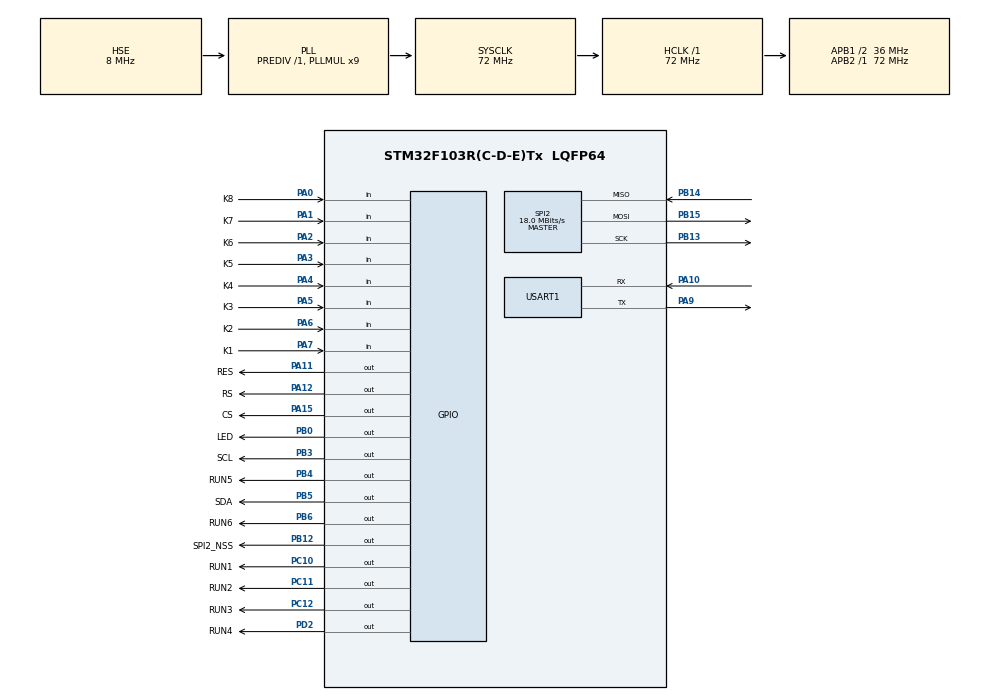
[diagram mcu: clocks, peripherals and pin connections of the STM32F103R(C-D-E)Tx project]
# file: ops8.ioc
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Dma.Request0=SPI2_TX
Dma.Request1=SPI2_RX
Dma.SPI2_RX.1.Direction=DMA_PERIPH_TO_MEMORY
Dma.SPI2_RX.1.Instance=DMA1_Channel4
Dma.SPI2_RX.1.MemDataAlignment=DMA_MDATAALIGN_BYTE
Dma.SPI2_RX.1.MemInc=DMA_MINC_ENABLE
Dma.SPI2_RX.1.Mode=DMA_NORMAL
Dma.SPI2_RX.1.PeriphDataAlignment=DMA_PDATAALIGN_BYTE
Dma.SPI2_RX.1.PeriphInc=DMA_PINC_DISABLE
Dma.SPI2_RX.1.Priority=DMA_PRIORITY_LOW
Dma.SPI2_TX.0.Direction=DMA_MEMORY_TO_PERIPH
Dma.SPI2_TX.0.Instance=DMA1_Channel5
Dma.SPI2_TX.0.MemDataAlignment=DMA_MDATAALIGN_BYTE
Dma.SPI2_TX.0.MemInc=DMA_MINC_ENABLE
Dma.SPI2_TX.0.Mode=DMA_NORMAL
Dma.SPI2_TX.0.PeriphDataAlignment=DMA_PDATAALIGN_BYTE
Dma.SPI2_TX.0.PeriphInc=DMA_PINC_DISABLE
Dma.SPI2_TX.0.Priority=DMA_PRIORITY_LOW
Mcu.Family=STM32F1
Mcu.Name=STM32F103R(C-D-E)Tx
Mcu.Package=LQFP64
NVIC.DMA1_Channel4_IRQn=true\:0\:0\:false\:false\:true\:false
NVIC.DMA1_Channel5_IRQn=true\:0\:0\:false\:false\:true\:false
NVIC.PriorityGroup=NVIC_PRIORITYGROUP_4
NVIC.SPI2_IRQn=true\:0\:0\:false\:false\:true\:true
NVIC.USART1_IRQn=true\:0\:0\:false\:false\:true\:true
PA0-WKUP.GPIO_Label=K8
PA0-WKUP.Signal=GPIO_Input
PA1.GPIO_Label=K7
PA1.Signal=GPIO_Input
PA10.Mode=Asynchronous
PA10.Signal=USART1_RX
PA11.GPIO_Label=RES
PA11.Signal=GPIO_Output
PA12.GPIO_Label=RS
PA12.Signal=GPIO_Output
PA15.GPIO_Label=CS
PA15.Signal=GPIO_Output
PA2.GPIO_Label=K6
PA2.Signal=GPIO_Input
PA3.GPIO_Label=K5
PA3.Signal=GPIO_Input
PA4.GPIO_Label=K4
PA4.Signal=GPIO_Input
PA5.GPIO_Label=K3
PA5.Signal=GPIO_Input
PA6.GPIO_Label=K2
PA6.Signal=GPIO_Input
PA7.GPIO_Label=K1
PA7.Signal=GPIO_Input
PA9.Mode=Asynchronous
PA9.Signal=USART1_TX
PB0.GPIO_Label=LED
PB0.Signal=GPIO_Output
PB12.GPIO_Label=SPI2_NSS
PB12.Signal=GPIO_Output
PB13.Mode=Full_Duplex_Master
PB13.Signal=SPI2_SCK
PB14.Mode=Full_Duplex_Master
PB14.Signal=SPI2_MISO
PB15.Mode=Full_Duplex_Master
PB15.Signal=SPI2_MOSI
PB3.GPIO_Label=SCL
PB3.Signal=GPIO_Output
PB4.GPIO_Label=RUN5
PB4.Signal=GPIO_Output
PB5.GPIO_Label=SDA
PB5.Signal=GPIO_Output
PB6.GPIO_Label=RUN6
PB6.Signal=GPIO_Output
PC10.GPIO_Label=RUN1
PC10.Signal=GPIO_Output
PC11.GPIO_Label=RUN2
PC11.Signal=GPIO_Output
PC12.GPIO_Label=RUN3
PC12.Signal=GPIO_Output
PD0-OSC_IN.Mode=HSE-External-Oscillator
PD0-OSC_IN.Signal=RCC_OSC_IN
PD1-OSC_OUT.Mode=HSE-External-Oscillator
PD1-OSC_OUT.Signal=RCC_OSC_OUT
PD2.GPIO_Label=RUN4
PD2.Signal=GPIO_Output
ProjectManager.HeapSize=0x200
ProjectManager.StackSize=0x400
ProjectManager.TargetToolchain=MDK-ARM V5
RCC.AHBFreq_Value=72000000
RCC.APB1CLKDivider=RCC_HCLK_DIV2
RCC.APB1Freq_Value=36000000
RCC.APB1TimFreq_Value=72000000
RCC.APB2Freq_Value=72000000
RCC.APB2TimFreq_Value=72000000
RCC.HCLKFreq_Value=72000000
RCC.PLLMUL=RCC_PLL_MUL9
RCC.PLLSourceVirtual=RCC_PLLSOURCE_HSE
RCC.SYSCLKFreq_VALUE=72000000
RCC.SYSCLKSource=RCC_SYSCLKSOURCE_PLLCLK
RCC.USBFreq_Value=72000000
SPI2.BaudRatePrescaler=SPI_BAUDRATEPRESCALER_2
SPI2.CLKPhase=SPI_PHASE_2EDGE
SPI2.CLKPolarity=SPI_POLARITY_HIGH
SPI2.CalculateBaudRate=18.0 MBits/s
SPI2.Direction=SPI_DIRECTION_2LINES
SPI2.Mode=SPI_MODE_MASTER
SPI2.VirtualType=VM_MASTER
USART1.VirtualMode=VM_ASYNC
VP_SYS_VS_ND.Mode=No_Debug
board=ops8

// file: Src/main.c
/**
  ******************************************************************************
  * @file           : main.c
  * @brief          : Main program body
  ******************************************************************************
  ** This notice applies to any and all portions of this file
  * that are not between comment pairs USER CODE BEGIN and
  * USER CODE END. Other portions of this file, whether
  * inserted by the user or by software development tools
  * are owned by their respective copyright owners.
  *
  * COPYRIGHT(c) 2018 STMicroelectronics
  *
  * Redistribution and use in source and binary forms, with or without modification,
  * are permitted provided that the following conditions are met:
  *   1. Redistributions of source code must retain the above copyright notice,
  *      this list of conditions and the following disclaimer.
  *   2. Redistributions in binary form must reproduce the above copyright notice,
  *      this list of conditions and the following disclaimer in the documentation
  *      and/or other materials provided with the distribution.
  *   3. Neither the name of STMicroelectronics nor the names of its contributors
  *      may be used to endorse or promote products derived from this software
  *      without specific prior written permission.
  *
  * THIS SOFTWARE IS PROVIDED BY THE COPYRIGHT HOLDERS AND CONTRIBUTORS "AS IS"
  * AND ANY EXPRESS OR IMPLIED WARRANTIES, INCLUDING, BUT NOT LIMITED TO, THE
  * IMPLIED WARRANTIES OF MERCHANTABILITY AND FITNESS FOR A PARTICULAR PURPOSE ARE
  * DISCLAIMED. IN NO EVENT SHALL THE COPYRIGHT HOLDER OR CONTRIBUTORS BE LIABLE
  * FOR ANY DIRECT, INDIRECT, INCIDENTAL, SPECIAL, EXEMPLARY, OR CONSEQUENTIAL
  * DAMAGES (INCLUDING, BUT NOT LIMITED TO, PROCUREMENT OF SUBSTITUTE GOODS OR
  * SERVICES; LOSS OF USE, DATA, OR PROFITS; OR BUSINESS INTERRUPTION) HOWEVER
  * CAUSED AND ON ANY THEORY OF LIABILITY, WHETHER IN CONTRACT, STRICT LIABILITY,
  * OR TORT (INCLUDING NEGLIGENCE OR OTHERWISE) ARISING IN ANY WAY OUT OF THE USE
  * OF THIS SOFTWARE, EVEN IF ADVISED OF THE POSSIBILITY OF SUCH DAMAGE.
  *
  ******************************************************************************
  */
#include "main.h"
#include "stm32f1xx_hal.h"

SPI_HandleTypeDef hspi2;
DMA_HandleTypeDef hdma_spi2_tx;
DMA_HandleTypeDef hdma_spi2_rx;

UART_HandleTypeDef huart1;

/* USER CODE BEGIN PV */
/* Private variables ---------------------------------------------------------*/

/* USER CODE END PV */

void SystemClock_Config(void);
static void MX_GPIO_Init(void);
static void MX_DMA_Init(void);
static void MX_USART1_UART_Init(void);
static void MX_SPI2_Init(void);

/* USER CODE BEGIN PFP */
/* Private function prototypes -----------------------------------------------*/

/* USER CODE END PFP */

/* USER CODE BEGIN 0 */
void test(void)
{
}
/* USER CODE END 0 */

int main(void)
{
  /* USER CODE BEGIN 1 */
	test();
  /* USER CODE END 1 */

  /* MCU Configuration----------------------------------------------------------*/

  /* Reset of all peripherals, Initializes the Flash interface and the Systick. */
  HAL_Init();

  /* Configure the system clock */
  SystemClock_Config();

  /* Initialize all configured peripherals */
  MX_GPIO_Init();
  MX_DMA_Init();
  MX_USART1_UART_Init();
  MX_SPI2_Init();

  /* Infinite loop */
  while (1)
  {

  }

}

void SystemClock_Config(void)
{

  RCC_OscInitTypeDef RCC_OscInitStruct;
  RCC_ClkInitTypeDef RCC_ClkInitStruct;

    /**Initializes the CPU, AHB and APB busses clocks
    */
  RCC_OscInitStruct.OscillatorType = RCC_OSCILLATORTYPE_HSE;
  RCC_OscInitStruct.HSEState = RCC_HSE_ON;
  RCC_OscInitStruct.HSEPredivValue = RCC_HSE_PREDIV_DIV1;
  RCC_OscInitStruct.HSIState = RCC_HSI_ON;
  RCC_OscInitStruct.PLL.PLLState = RCC_PLL_ON;
  RCC_OscInitStruct.PLL.PLLSource = RCC_PLLSOURCE_HSE;
  RCC_OscInitStruct.PLL.PLLMUL = RCC_PLL_MUL9;
  if (HAL_RCC_OscConfig(&RCC_OscInitStruct) != HAL_OK)
  {
    _Error_Handler(__FILE__, __LINE__);
  }

    /**Initializes the CPU, AHB and APB busses clocks
    */
  RCC_ClkInitStruct.ClockType = RCC_CLOCKTYPE_HCLK|RCC_CLOCKTYPE_SYSCLK
                              |RCC_CLOCKTYPE_PCLK1|RCC_CLOCKTYPE_PCLK2;
  RCC_ClkInitStruct.SYSCLKSource = RCC_SYSCLKSOURCE_PLLCLK;
  RCC_ClkInitStruct.AHBCLKDivider = RCC_SYSCLK_DIV1;
  RCC_ClkInitStruct.APB1CLKDivider = RCC_HCLK_DIV2;
  RCC_ClkInitStruct.APB2CLKDivider = RCC_HCLK_DIV1;

  if (HAL_RCC_ClockConfig(&RCC_ClkInitStruct, FLASH_LATENCY_2) != HAL_OK)
  {
    _Error_Handler(__FILE__, __LINE__);
  }

    /**Configure the Systick interrupt time
    */
  HAL_SYSTICK_Config(HAL_RCC_GetHCLKFreq()/1000);

    /**Configure the Systick
    */
  HAL_SYSTICK_CLKSourceConfig(SYSTICK_CLKSOURCE_HCLK);

  /* SysTick_IRQn interrupt configuration */
  HAL_NVIC_SetPriority(SysTick_IRQn, 0, 0);
}

/* SPI2 init function */
static void MX_SPI2_Init(void)
{

  /* SPI2 parameter configuration*/
  hspi2.Instance = SPI2;
  hspi2.Init.Mode = SPI_MODE_MASTER;
  hspi2.Init.Direction = SPI_DIRECTION_2LINES;
  hspi2.Init.DataSize = SPI_DATASIZE_8BIT;
  hspi2.Init.CLKPolarity = SPI_POLARITY_HIGH;
  hspi2.Init.CLKPhase = SPI_PHASE_2EDGE;
  hspi2.Init.NSS = SPI_NSS_SOFT;
  hspi2.Init.BaudRatePrescaler = SPI_BAUDRATEPRESCALER_2;
  hspi2.Init.FirstBit = SPI_FIRSTBIT_MSB;
  hspi2.Init.TIMode = SPI_TIMODE_DISABLE;
  hspi2.Init.CRCCalculation = SPI_CRCCALCULATION_DISABLE;
  hspi2.Init.CRCPolynomial = 10;
  if (HAL_SPI_Init(&hspi2) != HAL_OK)
  {
    _Error_Handler(__FILE__, __LINE__);
  }

}

/* USART1 init function */
static void MX_USART1_UART_Init(void)
{

  huart1.Instance = USART1;
  huart1.Init.BaudRate = 115200;
  huart1.Init.WordLength = UART_WORDLENGTH_8B;
  huart1.Init.StopBits = UART_STOPBITS_1;
  huart1.Init.Parity = UART_PARITY_NONE;
  huart1.Init.Mode = UART_MODE_TX_RX;
  huart1.Init.HwFlowCtl = UART_HWCONTROL_NONE;
  huart1.Init.OverSampling = UART_OVERSAMPLING_16;
  if (HAL_UART_Init(&huart1) != HAL_OK)
  {
    _Error_Handler(__FILE__, __LINE__);
  }

}

static void MX_DMA_Init(void)
{
  /* DMA controller clock enable */
  __HAL_RCC_DMA1_CLK_ENABLE();

  /* DMA interrupt init */
  /* DMA1_Channel4_IRQn interrupt configuration */
  HAL_NVIC_SetPriority(DMA1_Channel4_IRQn, 0, 0);
  HAL_NVIC_EnableIRQ(DMA1_Channel4_IRQn);
  /* DMA1_Channel5_IRQn interrupt configuration */
  HAL_NVIC_SetPriority(DMA1_Channel5_IRQn, 0, 0);
  HAL_NVIC_EnableIRQ(DMA1_Channel5_IRQn);

}

/** Configure pins as
        * Analog
        * Input
        * Output
        * EVENT_OUT
        * EXTI
*/
static void MX_GPIO_Init(void)
{

  LL_GPIO_InitTypeDef GPIO_InitStruct;

  /* GPIO Ports Clock Enable */
  LL_APB2_GRP1_EnableClock(LL_APB2_GRP1_PERIPH_GPIOD);
  LL_APB2_GRP1_EnableClock(LL_APB2_GRP1_PERIPH_GPIOA);
  LL_APB2_GRP1_EnableClock(LL_APB2_GRP1_PERIPH_GPIOB);
  LL_APB2_GRP1_EnableClock(LL_APB2_GRP1_PERIPH_GPIOC);

  /**/
  LL_GPIO_ResetOutputPin(GPIOB, LED_Pin|SPI2_NSS_Pin|SCL_Pin|RUN5_Pin
                          |SDA_Pin|RUN6_Pin);

  /**/
  LL_GPIO_ResetOutputPin(GPIOA, RES_Pin|RS_Pin|CS_Pin);

  /**/
  LL_GPIO_ResetOutputPin(GPIOC, RUN1_Pin|RUN2_Pin|RUN3_Pin);

  /**/
  LL_GPIO_ResetOutputPin(RUN4_GPIO_Port, RUN4_Pin);

  /**/
  GPIO_InitStruct.Pin = K8_Pin|K7_Pin|K6_Pin|K5_Pin
                          |K4_Pin|K3_Pin|K2_Pin|K1_Pin;
  GPIO_InitStruct.Mode = LL_GPIO_MODE_FLOATING;
  LL_GPIO_Init(GPIOA, &GPIO_InitStruct);

  /**/
  GPIO_InitStruct.Pin = LED_Pin|SPI2_NSS_Pin|SCL_Pin|RUN5_Pin
                          |SDA_Pin|RUN6_Pin;
  GPIO_InitStruct.Mode = LL_GPIO_MODE_OUTPUT;
  GPIO_InitStruct.Speed = LL_GPIO_SPEED_FREQ_LOW;
  GPIO_InitStruct.OutputType = LL_GPIO_OUTPUT_PUSHPULL;
  LL_GPIO_Init(GPIOB, &GPIO_InitStruct);

  /**/
  GPIO_InitStruct.Pin = RES_Pin|RS_Pin|CS_Pin;
  GPIO_InitStruct.Mode = LL_GPIO_MODE_OUTPUT;
  GPIO_InitStruct.Speed = LL_GPIO_SPEED_FREQ_LOW;
  GPIO_InitStruct.OutputType = LL_GPIO_OUTPUT_PUSHPULL;
  LL_GPIO_Init(GPIOA, &GPIO_InitStruct);

  /**/
  GPIO_InitStruct.Pin = RUN1_Pin|RUN2_Pin|RUN3_Pin;
  GPIO_InitStruct.Mode = LL_GPIO_MODE_OUTPUT;
  GPIO_InitStruct.Speed = LL_GPIO_SPEED_FREQ_LOW;
  GPIO_InitStruct.OutputType = LL_GPIO_OUTPUT_PUSHPULL;
  LL_GPIO_Init(GPIOC, &GPIO_InitStruct);

  /**/
  GPIO_InitStruct.Pin = RUN4_Pin;
  GPIO_InitStruct.Mode = LL_GPIO_MODE_OUTPUT;
  GPIO_InitStruct.Speed = LL_GPIO_SPEED_FREQ_LOW;
  GPIO_InitStruct.OutputType = LL_GPIO_OUTPUT_PUSHPULL;
  LL_GPIO_Init(RUN4_GPIO_Port, &GPIO_InitStruct);

}

void _Error_Handler(char *file, int line)
{
  while(1)
  {
  }
}

/************************ (C) COPYRIGHT STMicroelectronics *****END OF FILE****/
